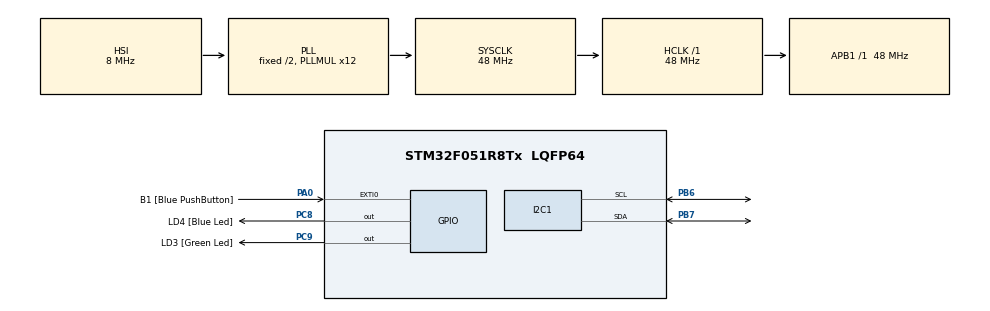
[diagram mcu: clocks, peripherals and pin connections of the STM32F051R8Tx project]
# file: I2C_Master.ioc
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I2C1.OwnAddress=3
Mcu.Family=STM32F0
Mcu.Name=STM32F051R8Tx
Mcu.Package=LQFP64
PA0.GPIO_Label=B1 [Blue PushButton]
PA0.GPIO_ModeDefaultEXTI=GPIO_MODE_EVT_RISING
PA0.Signal=GPXTI0
PA13.GPIO_Label=SWDIO
PA13.Mode=Serial_Wire
PA13.Signal=SYS_SWDIO
PA14.GPIO_Label=SWCLK
PA14.Mode=Serial_Wire
PA14.Signal=SYS_SWCLK
PB6.GPIO_Pu=GPIO_PULLUP
PB6.Mode=I2C
PB6.Signal=I2C1_SCL
PB7.GPIO_Pu=GPIO_PULLUP
PB7.Mode=I2C
PB7.Signal=I2C1_SDA
PC8.GPIO_Label=LD4 [Blue Led]
PC8.Signal=GPIO_Output
PC9.GPIO_Label=LD3 [Green Led]
PC9.Signal=GPIO_Output
ProjectManager.HeapSize=0x200
ProjectManager.StackSize=0x400
ProjectManager.TargetToolchain=MDK-ARM V5.32
RCC.AHBFreq_Value=48000000
RCC.APB1Freq_Value=48000000
RCC.APB1TimFreq_Value=48000000
RCC.HCLKFreq_Value=48000000
RCC.PLLMUL=RCC_PLL_MUL12
RCC.SYSCLKFreq_VALUE=48000000
RCC.SYSCLKSource=RCC_SYSCLKSOURCE_PLLCLK
board=STM32F0DISCOVERY

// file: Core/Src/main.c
/* USER CODE BEGIN Header */
/**
  ******************************************************************************
  * @file           : main.c
  * @brief          : Main program body
  ******************************************************************************
  * @attention
  *
  * <h2><center>&copy; Copyright (c) 2022 STMicroelectronics.
  * All rights reserved.</center></h2>
  *
  * This software component is licensed by ST under BSD 3-Clause license,
  * the "License"; You may not use this file except in compliance with the
  * License. You may obtain a copy of the License at:
  *                        opensource.org/licenses/BSD-3-Clause
  *
  ******************************************************************************
  */
/* USER CODE END Header */
#include "main.h"

I2C_HandleTypeDef hi2c1;

/* USER CODE BEGIN PV */
unsigned char RX_Buffer[1];

/* USER CODE END PV */

void SystemClock_Config(void);
static void MX_GPIO_Init(void);
static void MX_I2C1_Init(void);

int main(void)
{

  /* MCU Configuration--------------------------------------------------------*/

  /* Reset of all peripherals, Initializes the Flash interface and the Systick. */
  HAL_Init();

  /* Configure the system clock */
  SystemClock_Config();

  /* Initialize all configured peripherals */
  MX_GPIO_Init();
  MX_I2C1_Init();

  /* Infinite loop */
  while (1)
  {

    /* USER CODE BEGIN 3 */
		unsigned char TX_Buffer[1];
		TX_Buffer[0]='u';
   if(HAL_I2C_IsDeviceReady (&hi2c1, 0, 5, 100)==HAL_ERROR){
			HAL_GPIO_WritePin(GPIOC,GPIO_PIN_9,GPIO_PIN_SET);
			}
	 else{
	 HAL_GPIO_WritePin(GPIOC,GPIO_PIN_9,GPIO_PIN_RESET);
	 }
	 //HAL_I2C_Master_Receive(&hi2c1,0,RX_Buffer,1,100);
	 HAL_I2C_Slave_Receive(&hi2c1,RX_Buffer,1,100);
		if(HAL_GPIO_ReadPin(GPIOA,GPIO_PIN_0)){

		HAL_GPIO_TogglePin(GPIOC,GPIO_PIN_9);
			HAL_I2C_Master_Transmit(&hi2c1,0,(uint8_t*)TX_Buffer,1,100);
			HAL_Delay(200);
		}

  }
  /* USER CODE END 3 */
}

void SystemClock_Config(void)
{
  RCC_OscInitTypeDef RCC_OscInitStruct = {0};
  RCC_ClkInitTypeDef RCC_ClkInitStruct = {0};
  RCC_PeriphCLKInitTypeDef PeriphClkInit = {0};

  /** Initializes the RCC Oscillators according to the specified parameters
  * in the RCC_OscInitTypeDef structure.
  */
  RCC_OscInitStruct.OscillatorType = RCC_OSCILLATORTYPE_HSI;
  RCC_OscInitStruct.HSIState = RCC_HSI_ON;
  RCC_OscInitStruct.HSICalibrationValue = RCC_HSICALIBRATION_DEFAULT;
  RCC_OscInitStruct.PLL.PLLState = RCC_PLL_ON;
  RCC_OscInitStruct.PLL.PLLSource = RCC_PLLSOURCE_HSI;
  RCC_OscInitStruct.PLL.PLLMUL = RCC_PLL_MUL12;
  RCC_OscInitStruct.PLL.PREDIV = RCC_PREDIV_DIV1;
  if (HAL_RCC_OscConfig(&RCC_OscInitStruct) != HAL_OK)
  {
    Error_Handler();
  }
  /** Initializes the CPU, AHB and APB buses clocks
  */
  RCC_ClkInitStruct.ClockType = RCC_CLOCKTYPE_HCLK|RCC_CLOCKTYPE_SYSCLK
                              |RCC_CLOCKTYPE_PCLK1;
  RCC_ClkInitStruct.SYSCLKSource = RCC_SYSCLKSOURCE_PLLCLK;
  RCC_ClkInitStruct.AHBCLKDivider = RCC_SYSCLK_DIV1;
  RCC_ClkInitStruct.APB1CLKDivider = RCC_HCLK_DIV1;

  if (HAL_RCC_ClockConfig(&RCC_ClkInitStruct, FLASH_LATENCY_1) != HAL_OK)
  {
    Error_Handler();
  }
  PeriphClkInit.PeriphClockSelection = RCC_PERIPHCLK_I2C1;
  PeriphClkInit.I2c1ClockSelection = RCC_I2C1CLKSOURCE_HSI;
  if (HAL_RCCEx_PeriphCLKConfig(&PeriphClkInit) != HAL_OK)
  {
    Error_Handler();
  }
}

static void MX_I2C1_Init(void)
{

  hi2c1.Instance = I2C1;
  hi2c1.Init.Timing = 0x2000090E;
  hi2c1.Init.OwnAddress1 = 6;
  hi2c1.Init.AddressingMode = I2C_ADDRESSINGMODE_7BIT;
  hi2c1.Init.DualAddressMode = I2C_DUALADDRESS_DISABLE;
  hi2c1.Init.OwnAddress2 = 0;
  hi2c1.Init.OwnAddress2Masks = I2C_OA2_NOMASK;
  hi2c1.Init.GeneralCallMode = I2C_GENERALCALL_DISABLE;
  hi2c1.Init.NoStretchMode = I2C_NOSTRETCH_DISABLE;
  if (HAL_I2C_Init(&hi2c1) != HAL_OK)
  {
    Error_Handler();
  }
  /** Configure Analogue filter
  */
  if (HAL_I2CEx_ConfigAnalogFilter(&hi2c1, I2C_ANALOGFILTER_ENABLE) != HAL_OK)
  {
    Error_Handler();
  }
  /** Configure Digital filter
  */
  if (HAL_I2CEx_ConfigDigitalFilter(&hi2c1, 0) != HAL_OK)
  {
    Error_Handler();
  }

}

static void MX_GPIO_Init(void)
{
  GPIO_InitTypeDef GPIO_InitStruct = {0};

  /* GPIO Ports Clock Enable */
  __HAL_RCC_GPIOA_CLK_ENABLE();
  __HAL_RCC_GPIOC_CLK_ENABLE();
  __HAL_RCC_GPIOB_CLK_ENABLE();

  /*Configure GPIO pin Output Level */
  HAL_GPIO_WritePin(GPIOC, LD4_Pin|LD3_Pin, GPIO_PIN_RESET);

  /*Configure GPIO pin : B1_Pin */
  GPIO_InitStruct.Pin = B1_Pin;
  GPIO_InitStruct.Mode = GPIO_MODE_EVT_RISING;
  GPIO_InitStruct.Pull = GPIO_NOPULL;
  HAL_GPIO_Init(B1_GPIO_Port, &GPIO_InitStruct);

  /*Configure GPIO pins : LD4_Pin LD3_Pin */
  GPIO_InitStruct.Pin = LD4_Pin|LD3_Pin;
  GPIO_InitStruct.Mode = GPIO_MODE_OUTPUT_PP;
  GPIO_InitStruct.Pull = GPIO_NOPULL;
  GPIO_InitStruct.Speed = GPIO_SPEED_FREQ_LOW;
  HAL_GPIO_Init(GPIOC, &GPIO_InitStruct);

}

void Error_Handler(void)
{
  __disable_irq();
  while (1)
  {
  }
}

/************************ (C) COPYRIGHT STMicroelectronics *****END OF FILE****/
